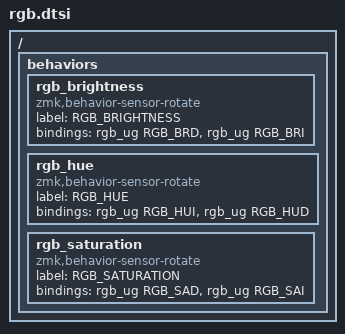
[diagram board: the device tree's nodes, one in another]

/ {

  behaviors {

    rgb_brightness: rgb_brightness {
        compatible = "zmk,behavior-sensor-rotate";
        label = "RGB_BRIGHTNESS";
        #sensor-binding-cells = <0>;
        bindings = <&rgb_ug RGB_BRD>, <&rgb_ug RGB_BRI>;
    };

    rgb_hue: rgb_hue {
        compatible = "zmk,behavior-sensor-rotate";
        label = "RGB_HUE";
        #sensor-binding-cells = <0>;
        bindings = <&rgb_ug RGB_HUI>, <&rgb_ug RGB_HUD>;
    };

    rgb_saturation: rgb_saturation {
        compatible = "zmk,behavior-sensor-rotate";
        label = "RGB_SATURATION";
        #sensor-binding-cells = <0>;
        bindings = <&rgb_ug RGB_SAD>, <&rgb_ug RGB_SAI>;
    };
  };
};
